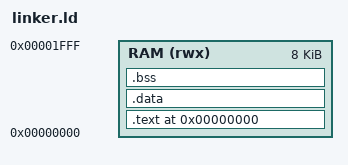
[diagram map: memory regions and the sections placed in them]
OUTPUT_ARCH(riscv)
ENTRY(_start)

MEMORY
{
    RAM (rwx) : ORIGIN = 0x00000000, LENGTH = 8K
}

SECTIONS
{
    . = ORIGIN(RAM);

    .text : ALIGN(4)
    {
        KEEP(*(.text.start))
        *(.text .text.*)
        *(.rodata .rodata.*)
    } > RAM

    .data : ALIGN(4)
    {
        *(.data .data.*)
    } > RAM

    .bss (NOLOAD) : ALIGN(4)
    {
        _bss_start = .;
        *(.bss .bss.*)
        *(COMMON)
        . = ALIGN(4);
        _bss_end = .;
    } > RAM

    /* Kernel stack grows down from the top of RAM. Task stacks live in .bss. */
    _stack_top = ORIGIN(RAM) + LENGTH(RAM);

    /DISCARD/ :
    {
        *(.comment)
        *(.riscv.attributes)
    }
}
